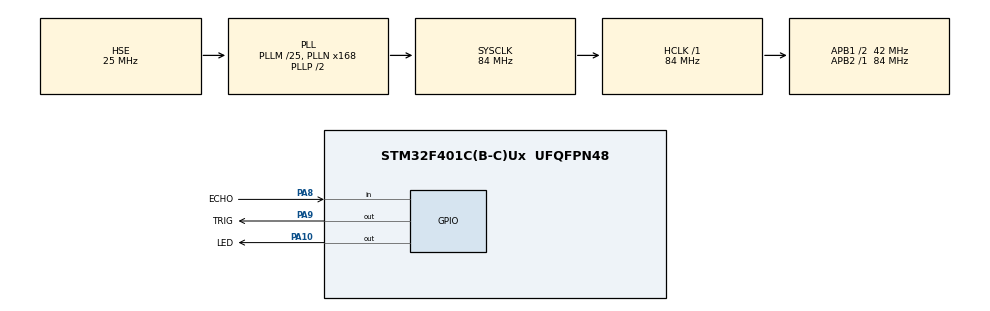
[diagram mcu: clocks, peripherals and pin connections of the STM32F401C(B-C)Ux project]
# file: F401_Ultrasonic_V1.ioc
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Mcu.Family=STM32F4
Mcu.Name=STM32F401C(B-C)Ux
Mcu.Package=UFQFPN48
NVIC.PriorityGroup=NVIC_PRIORITYGROUP_4
PA10.GPIO_Label=LED
PA10.Signal=GPIO_Output
PA13.Mode=Serial_Wire
PA13.Signal=SYS_JTMS-SWDIO
PA14.Mode=Serial_Wire
PA14.Signal=SYS_JTCK-SWCLK
PA8.GPIO_Label=ECHO
PA8.Signal=GPIO_Input
PA9.GPIO_Label=TRIG
PA9.Signal=GPIO_Output
PH0\ -\ OSC_IN.Mode=HSE-External-Oscillator
PH0\ -\ OSC_IN.Signal=RCC_OSC_IN
PH1\ -\ OSC_OUT.Mode=HSE-External-Oscillator
PH1\ -\ OSC_OUT.Signal=RCC_OSC_OUT
ProjectManager.HeapSize=0x200
ProjectManager.StackSize=0x400
ProjectManager.TargetToolchain=STM32CubeIDE
RCC.48MHZClocksFreq_Value=42000000
RCC.AHBFreq_Value=84000000
RCC.APB1CLKDivider=RCC_HCLK_DIV2
RCC.APB1Freq_Value=42000000
RCC.APB1TimFreq_Value=84000000
RCC.APB2Freq_Value=84000000
RCC.APB2TimFreq_Value=84000000
RCC.CortexFreq_Value=84000000
RCC.HCLKFreq_Value=84000000
RCC.HSE_VALUE=25000000
RCC.HSI_VALUE=16000000
RCC.LSE_VALUE=32768
RCC.PLLM=25
RCC.PLLN=168
RCC.PLLSourceVirtual=RCC_PLLSOURCE_HSE
RCC.SYSCLKFreq_VALUE=84000000
RCC.SYSCLKSource=RCC_SYSCLKSOURCE_PLLCLK
RCC.VCOOutputFreq_Value=168000000
TIM1.Prescaler=79
VP_TIM1_VS_ClockSourceINT.Mode=Internal
board=custom

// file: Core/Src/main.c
/* USER CODE BEGIN Header */
/**
  ******************************************************************************
  * @file           : main.c
  * @brief          : Main program body
  ******************************************************************************
  * @attention
  *
  * Copyright (c) 2024 STMicroelectronics.
  * All rights reserved.
  *
  * This software is licensed under terms that can be found in the LICENSE file
  * in the root directory of this software component.
  * If no LICENSE file comes with this software, it is provided AS-IS.
  *
  ******************************************************************************
  */
/* USER CODE END Header */
#include "main.h"
#include "tim.h"
#include "gpio.h"

/* USER CODE BEGIN Includes */

	/* ULTRASONIC */

		#define TRIG_PIN GPIO_PIN_9
		#define TRIG_PORT GPIOA
		#define ECHO_PIN GPIO_PIN_8
		#define ECHO_PORT GPIOA

	/* LED */

		#define LED_PIN GPIO_PIN_10
		#define LED_PORT GPIOA

/* USER CODE END Includes */

/* USER CODE BEGIN PD */

	/* ULTRASONIC */

		uint32_t pMillis;
		uint32_t val1 = 0;
		uint32_t val2 = 0;
		uint16_t distance = 0;

/* USER CODE END PD */

void SystemClock_Config(void);

/* USER CODE BEGIN 0 */

	/* ULTRASONIC */

		void Ultrasonic_Start(){
			HAL_GPIO_WritePin(TRIG_PORT, TRIG_PIN, GPIO_PIN_SET);
			__HAL_TIM_SET_COUNTER(&htim1, 0);
			while (__HAL_TIM_GET_COUNTER (&htim1) < 10);  // wait for 10 ms
				  HAL_GPIO_WritePin(TRIG_PORT, TRIG_PIN, GPIO_PIN_RESET);

				  pMillis = HAL_GetTick();
			while (!(HAL_GPIO_ReadPin (ECHO_PORT, ECHO_PIN)) && pMillis + 10 >  HAL_GetTick());
				  val1 = __HAL_TIM_GET_COUNTER (&htim1);

				  pMillis = HAL_GetTick();
			while ((HAL_GPIO_ReadPin (ECHO_PORT, ECHO_PIN)) && pMillis + 50 > HAL_GetTick());
				  val2 = __HAL_TIM_GET_COUNTER (&htim1);

				  distance = (val2-val1)* 0.034/2;
				  HAL_Delay(50);
		}

/* USER CODE END 0 */

int main(void)
{

  /* MCU Configuration--------------------------------------------------------*/

  /* Reset of all peripherals, Initializes the Flash interface and the Systick. */
  HAL_Init();

  /* Configure the system clock */
  SystemClock_Config();

  /* Initialize all configured peripherals */
  MX_GPIO_Init();
  MX_TIM1_Init();
  /* USER CODE BEGIN 2 */

	/* ULTRASONIC */

		HAL_TIM_Base_Start(&htim1);
		HAL_GPIO_WritePin(TRIG_PORT, TRIG_PIN, GPIO_PIN_RESET);

  /* USER CODE END 2 */

  /* Infinite loop */
  while (1)
  {

    /* USER CODE BEGIN 3 */

	  	  Ultrasonic_Start();

	  	  if(distance<=20){
	  	  	 HAL_GPIO_WritePin(LED_PORT,LED_PIN, 1);
	  	  }else{
	  	     HAL_GPIO_WritePin(LED_PORT,LED_PIN, 0);
	  	  }

  }
  /* USER CODE END 3 */
}

void SystemClock_Config(void)
{
  RCC_OscInitTypeDef RCC_OscInitStruct = {0};
  RCC_ClkInitTypeDef RCC_ClkInitStruct = {0};

  /** Configure the main internal regulator output voltage
  */
  __HAL_RCC_PWR_CLK_ENABLE();
  __HAL_PWR_VOLTAGESCALING_CONFIG(PWR_REGULATOR_VOLTAGE_SCALE2);

  /** Initializes the RCC Oscillators according to the specified parameters
  * in the RCC_OscInitTypeDef structure.
  */
  RCC_OscInitStruct.OscillatorType = RCC_OSCILLATORTYPE_HSE;
  RCC_OscInitStruct.HSEState = RCC_HSE_ON;
  RCC_OscInitStruct.PLL.PLLState = RCC_PLL_ON;
  RCC_OscInitStruct.PLL.PLLSource = RCC_PLLSOURCE_HSE;
  RCC_OscInitStruct.PLL.PLLM = 25;
  RCC_OscInitStruct.PLL.PLLN = 168;
  RCC_OscInitStruct.PLL.PLLP = RCC_PLLP_DIV2;
  RCC_OscInitStruct.PLL.PLLQ = 4;
  if (HAL_RCC_OscConfig(&RCC_OscInitStruct) != HAL_OK)
  {
    Error_Handler();
  }

  /** Initializes the CPU, AHB and APB buses clocks
  */
  RCC_ClkInitStruct.ClockType = RCC_CLOCKTYPE_HCLK|RCC_CLOCKTYPE_SYSCLK
                              |RCC_CLOCKTYPE_PCLK1|RCC_CLOCKTYPE_PCLK2;
  RCC_ClkInitStruct.SYSCLKSource = RCC_SYSCLKSOURCE_PLLCLK;
  RCC_ClkInitStruct.AHBCLKDivider = RCC_SYSCLK_DIV1;
  RCC_ClkInitStruct.APB1CLKDivider = RCC_HCLK_DIV2;
  RCC_ClkInitStruct.APB2CLKDivider = RCC_HCLK_DIV1;

  if (HAL_RCC_ClockConfig(&RCC_ClkInitStruct, FLASH_LATENCY_2) != HAL_OK)
  {
    Error_Handler();
  }
}

void Error_Handler(void)
{
  __disable_irq();
  while (1)
  {
  }
}
